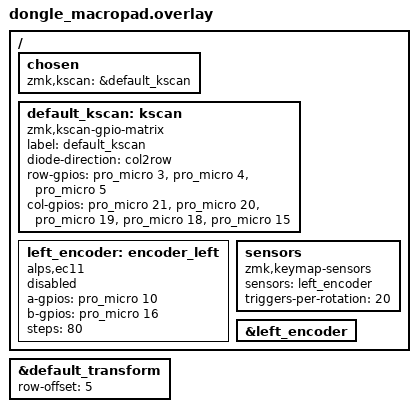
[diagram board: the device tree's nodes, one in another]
#include <dt-bindings/zmk/matrix_transform.h>

&default_transform {
    row-offset = <5>;
};

/ {
    chosen {
        zmk,kscan = &default_kscan;
    };

    default_kscan: kscan {
        compatible = "zmk,kscan-gpio-matrix";
        label = "default_kscan";
        diode-direction = "col2row";

        row-gpios = <&pro_micro 3 (GPIO_ACTIVE_HIGH | GPIO_PULL_DOWN)>,
                    <&pro_micro 4 (GPIO_ACTIVE_HIGH | GPIO_PULL_DOWN)>,
                    <&pro_micro 5 (GPIO_ACTIVE_HIGH | GPIO_PULL_DOWN)>;
        
        col-gpios = <&pro_micro 21 GPIO_ACTIVE_HIGH>,
                    <&pro_micro 20 GPIO_ACTIVE_HIGH>,
                    <&pro_micro 19 GPIO_ACTIVE_HIGH>,
                    <&pro_micro 18 GPIO_ACTIVE_HIGH>,
                    <&pro_micro 15 GPIO_ACTIVE_HIGH>;
    };

    left_encoder: encoder_left {
        compatible = "alps,ec11";
        a-gpios = <&pro_micro 10 (GPIO_ACTIVE_HIGH | GPIO_PULL_UP)>;
        b-gpios = <&pro_micro 16 (GPIO_ACTIVE_HIGH | GPIO_PULL_UP)>;
        steps = <80>;
        status = "disabled";
    };

    sensors: sensors {
        compatible = "zmk,keymap-sensors";
        sensors = <&left_encoder>;
        triggers-per-rotation = <20>;
    };

    &left_encoder {
        status = "okay";
    };
};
